AUTOSAR XML (schema 4-0-3)
package /BswM/ServiceSwComponentTypes
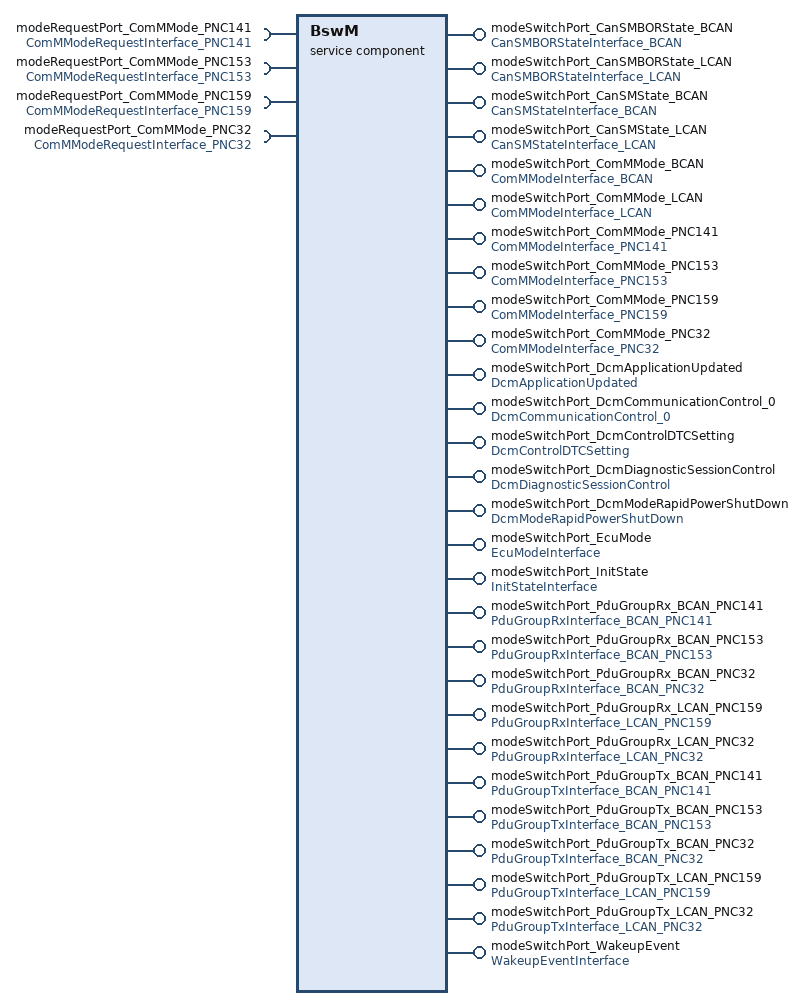
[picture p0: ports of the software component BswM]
  service sw component type BswM
    4 x require port:
      modeRequestPort_ComMMode_PNC141: nonqueued-receiver-com-spec=ComMMode_PNC141, required-interface=ComMModeRequestInterface_PNC141
      modeRequestPort_ComMMode_PNC153: nonqueued-receiver-com-spec=ComMMode_PNC153, required-interface=ComMModeRequestInterface_PNC153
      modeRequestPort_ComMMode_PNC159: nonqueued-receiver-com-spec=ComMMode_PNC159, required-interface=ComMModeRequestInterface_PNC159
      modeRequestPort_ComMMode_PNC32: nonqueued-receiver-com-spec=ComMMode_PNC32, required-interface=ComMModeRequestInterface_PNC32
    28 x provide port:
      modeSwitchPort_CanSMBORState_BCAN: mode-switch-sender-com-spec{enhanced-mode-api=false, mode-group=CanSMBORState_BCAN, queue-length=1}, provided-interface=CanSMBORStateInterface_BCAN
      modeSwitchPort_CanSMBORState_LCAN: mode-switch-sender-com-spec{enhanced-mode-api=false, mode-group=CanSMBORState_LCAN, queue-length=1}, provided-interface=CanSMBORStateInterface_LCAN
      modeSwitchPort_CanSMState_BCAN: mode-switch-sender-com-spec{enhanced-mode-api=false, mode-group=CanSMState_BCAN, queue-length=1}, provided-interface=CanSMStateInterface_BCAN
      modeSwitchPort_CanSMState_LCAN: mode-switch-sender-com-spec{enhanced-mode-api=false, mode-group=CanSMState_LCAN, queue-length=1}, provided-interface=CanSMStateInterface_LCAN
      modeSwitchPort_ComMMode_BCAN: mode-switch-sender-com-spec{enhanced-mode-api=false, mode-group=ComMMode_BCAN, queue-length=1}, provided-interface=ComMModeInterface_BCAN
      modeSwitchPort_ComMMode_LCAN: mode-switch-sender-com-spec{enhanced-mode-api=false, mode-group=ComMMode_LCAN, queue-length=1}, provided-interface=ComMModeInterface_LCAN
      modeSwitchPort_ComMMode_PNC141: mode-switch-sender-com-spec{enhanced-mode-api=false, mode-group=ComMMode_PNC141, queue-length=1}, provided-interface=ComMModeInterface_PNC141
      modeSwitchPort_ComMMode_PNC153: mode-switch-sender-com-spec{enhanced-mode-api=false, mode-group=ComMMode_PNC153, queue-length=1}, provided-interface=ComMModeInterface_PNC153
      modeSwitchPort_ComMMode_PNC159: mode-switch-sender-com-spec{enhanced-mode-api=false, mode-group=ComMMode_PNC159, queue-length=1}, provided-interface=ComMModeInterface_PNC159
      modeSwitchPort_ComMMode_PNC32: mode-switch-sender-com-spec{enhanced-mode-api=false, mode-group=ComMMode_PNC32, queue-length=1}, provided-interface=ComMModeInterface_PNC32
      modeSwitchPort_DcmApplicationUpdated: mode-switch-sender-com-spec{enhanced-mode-api=false, mode-group=DcmApplicationUpdated, queue-length=1}, provided-interface=DcmApplicationUpdated
      modeSwitchPort_DcmCommunicationControl_0: mode-switch-sender-com-spec{enhanced-mode-api=false, mode-group=DcmCommunicationControl_0, queue-length=1}, provided-interface=DcmCommunicationControl_0
      modeSwitchPort_DcmControlDTCSetting: mode-switch-sender-com-spec{enhanced-mode-api=false, mode-group=DcmControlDTCSetting, queue-length=1}, provided-interface=DcmControlDTCSetting
      modeSwitchPort_DcmDiagnosticSessionControl: mode-switch-sender-com-spec{enhanced-mode-api=false, mode-group=DcmDiagnosticSessionControl, queue-length=1}, provided-interface=DcmDiagnosticSessionControl
      modeSwitchPort_DcmModeRapidPowerShutDown: mode-switch-sender-com-spec{enhanced-mode-api=false, mode-group=DcmModeRapidPowerShutDown, queue-length=1}, provided-interface=DcmModeRapidPowerShutDown
      modeSwitchPort_EcuMode: mode-switch-sender-com-spec{enhanced-mode-api=false, mode-group=EcuMode, queue-length=1}, provided-interface=EcuModeInterface
      modeSwitchPort_InitState: mode-switch-sender-com-spec{enhanced-mode-api=false, mode-group=InitState, queue-length=1}, provided-interface=InitStateInterface
      modeSwitchPort_PduGroupRx_BCAN_PNC141: mode-switch-sender-com-spec{enhanced-mode-api=false, mode-group=PduGroupRx_BCAN_PNC141, queue-length=1}, provided-interface=PduGroupRxInterface_BCAN_PNC141
      modeSwitchPort_PduGroupRx_BCAN_PNC153: mode-switch-sender-com-spec{enhanced-mode-api=false, mode-group=PduGroupRx_BCAN_PNC153, queue-length=1}, provided-interface=PduGroupRxInterface_BCAN_PNC153
      modeSwitchPort_PduGroupRx_BCAN_PNC32: mode-switch-sender-com-spec{enhanced-mode-api=false, mode-group=PduGroupRx_BCAN_PNC32, queue-length=1}, provided-interface=PduGroupRxInterface_BCAN_PNC32
      modeSwitchPort_PduGroupRx_LCAN_PNC159: mode-switch-sender-com-spec{enhanced-mode-api=false, mode-group=PduGroupRx_LCAN_PNC159, queue-length=1}, provided-interface=PduGroupRxInterface_LCAN_PNC159
      modeSwitchPort_PduGroupRx_LCAN_PNC32: mode-switch-sender-com-spec{enhanced-mode-api=false, mode-group=PduGroupRx_LCAN_PNC32, queue-length=1}, provided-interface=PduGroupRxInterface_LCAN_PNC32
      modeSwitchPort_PduGroupTx_BCAN_PNC141: mode-switch-sender-com-spec{enhanced-mode-api=false, mode-group=PduGroupTx_BCAN_PNC141, queue-length=1}, provided-interface=PduGroupTxInterface_BCAN_PNC141
      modeSwitchPort_PduGroupTx_BCAN_PNC153: mode-switch-sender-com-spec{enhanced-mode-api=false, mode-group=PduGroupTx_BCAN_PNC153, queue-length=1}, provided-interface=PduGroupTxInterface_BCAN_PNC153
      modeSwitchPort_PduGroupTx_BCAN_PNC32: mode-switch-sender-com-spec{enhanced-mode-api=false, mode-group=PduGroupTx_BCAN_PNC32, queue-length=1}, provided-interface=PduGroupTxInterface_BCAN_PNC32
      modeSwitchPort_PduGroupTx_LCAN_PNC159: mode-switch-sender-com-spec{enhanced-mode-api=false, mode-group=PduGroupTx_LCAN_PNC159, queue-length=1}, provided-interface=PduGroupTxInterface_LCAN_PNC159
      modeSwitchPort_PduGroupTx_LCAN_PNC32: mode-switch-sender-com-spec{enhanced-mode-api=false, mode-group=PduGroupTx_LCAN_PNC32, queue-length=1}, provided-interface=PduGroupTxInterface_LCAN_PNC32
      modeSwitchPort_WakeupEvent: mode-switch-sender-com-spec{enhanced-mode-api=false, mode-group=WakeupEvent, queue-length=1}, provided-interface=WakeupEventInterface
    behavior SwcIB_BswM: data-type-mapping=MAP_ComMMode, handle-termination-and-restart=NO-SUPPORT
      4 x data received event:
        DRE_BswM_Immediate_SwcModeRequest_ComMMode_PNC141_modeRequestPort_ComMMode_PNC141_ComMMode_PNC141: start-on-event=BswM_Immediate_SwcModeRequest_ComMMode_PNC141, data=modeRequestPort_ComMMode_PNC141.ComMMode_PNC141
        DRE_BswM_Immediate_SwcModeRequest_ComMMode_PNC153_modeRequestPort_ComMMode_PNC153_ComMMode_PNC153: start-on-event=BswM_Immediate_SwcModeRequest_ComMMode_PNC153, data=modeRequestPort_ComMMode_PNC153.ComMMode_PNC153
        DRE_BswM_Immediate_SwcModeRequest_ComMMode_PNC159_modeRequestPort_ComMMode_PNC159_ComMMode_PNC159: start-on-event=BswM_Immediate_SwcModeRequest_ComMMode_PNC159, data=modeRequestPort_ComMMode_PNC159.ComMMode_PNC159
        DRE_BswM_Immediate_SwcModeRequest_ComMMode_PNC32_modeRequestPort_ComMMode_PNC32_ComMMode_PNC32: start-on-event=BswM_Immediate_SwcModeRequest_ComMMode_PNC32, data=modeRequestPort_ComMMode_PNC32.ComMMode_PNC32
      32 x runnable:
        BswM_ActionList_RteSwitch_CanSMBORState_BCAN: can-be-invoked-concurrently=true
          mode switch point MSP_BswM_ActionList_RteSwitch_CanSMBORState_BCAN_modeSwitchPort_CanSMBORState_BCAN_CanSMBORState_BCAN: category=TOOL_CONFIGURED, mode-group=modeSwitchPort_CanSMBORState_BCAN.CanSMBORState_BCAN
        BswM_ActionList_RteSwitch_CanSMBORState_LCAN: can-be-invoked-concurrently=true
          mode switch point MSP_BswM_ActionList_RteSwitch_CanSMBORState_LCAN_modeSwitchPort_CanSMBORState_LCAN_CanSMBORState_LCAN: category=TOOL_CONFIGURED, mode-group=modeSwitchPort_CanSMBORState_LCAN.CanSMBORState_LCAN
        BswM_ActionList_RteSwitch_CanSMState_BCAN: can-be-invoked-concurrently=true
          mode switch point MSP_BswM_ActionList_RteSwitch_CanSMState_BCAN_modeSwitchPort_CanSMState_BCAN_CanSMState_BCAN: category=TOOL_CONFIGURED, mode-group=modeSwitchPort_CanSMState_BCAN.CanSMState_BCAN
        BswM_ActionList_RteSwitch_CanSMState_LCAN: can-be-invoked-concurrently=true
          mode switch point MSP_BswM_ActionList_RteSwitch_CanSMState_LCAN_modeSwitchPort_CanSMState_LCAN_CanSMState_LCAN: category=TOOL_CONFIGURED, mode-group=modeSwitchPort_CanSMState_LCAN.CanSMState_LCAN
        BswM_ActionList_RteSwitch_ComMMode_BCAN: can-be-invoked-concurrently=true
          mode switch point MSP_BswM_ActionList_RteSwitch_ComMMode_BCAN_modeSwitchPort_ComMMode_BCAN_ComMMode_BCAN: category=TOOL_CONFIGURED, mode-group=modeSwitchPort_ComMMode_BCAN.ComMMode_BCAN
        BswM_ActionList_RteSwitch_ComMMode_LCAN: can-be-invoked-concurrently=true
          mode switch point MSP_BswM_ActionList_RteSwitch_ComMMode_LCAN_modeSwitchPort_ComMMode_LCAN_ComMMode_LCAN: category=TOOL_CONFIGURED, mode-group=modeSwitchPort_ComMMode_LCAN.ComMMode_LCAN
        BswM_ActionList_RteSwitch_ComMMode_PNC141: can-be-invoked-concurrently=true
          mode switch point MSP_BswM_ActionList_RteSwitch_ComMMode_PNC141_modeSwitchPort_ComMMode_PNC141_ComMMode_PNC141: category=TOOL_CONFIGURED, mode-group=modeSwitchPort_ComMMode_PNC141.ComMMode_PNC141
        BswM_ActionList_RteSwitch_ComMMode_PNC153: can-be-invoked-concurrently=true
          mode switch point MSP_BswM_ActionList_RteSwitch_ComMMode_PNC153_modeSwitchPort_ComMMode_PNC153_ComMMode_PNC153: category=TOOL_CONFIGURED, mode-group=modeSwitchPort_ComMMode_PNC153.ComMMode_PNC153
        BswM_ActionList_RteSwitch_ComMMode_PNC159: can-be-invoked-concurrently=true
          mode switch point MSP_BswM_ActionList_RteSwitch_ComMMode_PNC159_modeSwitchPort_ComMMode_PNC159_ComMMode_PNC159: category=TOOL_CONFIGURED, mode-group=modeSwitchPort_ComMMode_PNC159.ComMMode_PNC159
        BswM_ActionList_RteSwitch_ComMMode_PNC32: can-be-invoked-concurrently=true
          mode switch point MSP_BswM_ActionList_RteSwitch_ComMMode_PNC32_modeSwitchPort_ComMMode_PNC32_ComMMode_PNC32: category=TOOL_CONFIGURED, mode-group=modeSwitchPort_ComMMode_PNC32.ComMMode_PNC32
        BswM_ActionList_RteSwitch_DcmApplicationUpdated: can-be-invoked-concurrently=true
          mode switch point MSP_BswM_ActionList_RteSwitch_DcmApplicationUpdated_modeSwitchPort_DcmApplicationUpdated_DcmApplicationUpdated: category=TOOL_CONFIGURED, mode-group=modeSwitchPort_DcmApplicationUpdated.DcmApplicationUpdated
        BswM_ActionList_RteSwitch_DcmCommunicationControl_0: can-be-invoked-concurrently=true
          mode switch point MSP_BswM_ActionList_RteSwitch_DcmCommunicationControl_0_modeSwitchPort_DcmCommunicationControl_0_DcmCommunicationControl_0: category=TOOL_CONFIGURED, mode-group=modeSwitchPort_DcmCommunicationControl_0.DcmCommunicationControl_0
        BswM_ActionList_RteSwitch_DcmControlDTCSetting: can-be-invoked-concurrently=true
          mode switch point MSP_BswM_ActionList_RteSwitch_DcmControlDTCSetting_modeSwitchPort_DcmControlDTCSetting_DcmControlDTCSetting: category=TOOL_CONFIGURED, mode-group=modeSwitchPort_DcmControlDTCSetting.DcmControlDTCSetting
        BswM_ActionList_RteSwitch_DcmDiagnosticSessionControl: can-be-invoked-concurrently=true
          mode switch point MSP_BswM_ActionList_RteSwitch_DcmDiagnosticSessionControl_modeSwitchPort_DcmDiagnosticSessionControl_DcmDiagnosticSessionControl: category=TOOL_CONFIGURED, mode-group=modeSwitchPort_DcmDiagnosticSessionControl.DcmDiagnosticSessionControl
        BswM_ActionList_RteSwitch_DcmModeRapidPowerShutDown: can-be-invoked-concurrently=true
          mode switch point MSP_BswM_ActionList_RteSwitch_DcmModeRapidPowerShutDown_modeSwitchPort_DcmModeRapidPowerShutDown_DcmModeRapidPowerShutDown: category=TOOL_CONFIGURED, mode-group=modeSwitchPort_DcmModeRapidPowerShutDown.DcmModeRapidPowerShutDown
        BswM_ActionList_RteSwitch_EcuMode: can-be-invoked-concurrently=true
          mode switch point MSP_BswM_ActionList_RteSwitch_EcuMode_modeSwitchPort_EcuMode_EcuMode: category=TOOL_CONFIGURED, mode-group=modeSwitchPort_EcuMode.EcuMode
        BswM_ActionList_RteSwitch_InitState: can-be-invoked-concurrently=true
          mode switch point MSP_BswM_ActionList_RteSwitch_InitState_modeSwitchPort_InitState_InitState: category=TOOL_CONFIGURED, mode-group=modeSwitchPort_InitState.InitState
        BswM_ActionList_RteSwitch_PduGroupRx_BCAN_PNC141: can-be-invoked-concurrently=true
          mode switch point MSP_BswM_ActionList_RteSwitch_PduGroupRx_BCAN_PNC141_modeSwitchPort_PduGroupRx_BCAN_PNC141_PduGroupRx_BCAN_PNC141: category=TOOL_CONFIGURED, mode-group=modeSwitchPort_PduGroupRx_BCAN_PNC141.PduGroupRx_BCAN_PNC141
        BswM_ActionList_RteSwitch_PduGroupRx_BCAN_PNC153: can-be-invoked-concurrently=true
          mode switch point MSP_BswM_ActionList_RteSwitch_PduGroupRx_BCAN_PNC153_modeSwitchPort_PduGroupRx_BCAN_PNC153_PduGroupRx_BCAN_PNC153: category=TOOL_CONFIGURED, mode-group=modeSwitchPort_PduGroupRx_BCAN_PNC153.PduGroupRx_BCAN_PNC153
        BswM_ActionList_RteSwitch_PduGroupRx_BCAN_PNC32: can-be-invoked-concurrently=true
          mode switch point MSP_BswM_ActionList_RteSwitch_PduGroupRx_BCAN_PNC32_modeSwitchPort_PduGroupRx_BCAN_PNC32_PduGroupRx_BCAN_PNC32: category=TOOL_CONFIGURED, mode-group=modeSwitchPort_PduGroupRx_BCAN_PNC32.PduGroupRx_BCAN_PNC32
        BswM_ActionList_RteSwitch_PduGroupRx_LCAN_PNC159: can-be-invoked-concurrently=true
          mode switch point MSP_BswM_ActionList_RteSwitch_PduGroupRx_LCAN_PNC159_modeSwitchPort_PduGroupRx_LCAN_PNC159_PduGroupRx_LCAN_PNC159: category=TOOL_CONFIGURED, mode-group=modeSwitchPort_PduGroupRx_LCAN_PNC159.PduGroupRx_LCAN_PNC159
        BswM_ActionList_RteSwitch_PduGroupRx_LCAN_PNC32: can-be-invoked-concurrently=true
          mode switch point MSP_BswM_ActionList_RteSwitch_PduGroupRx_LCAN_PNC32_modeSwitchPort_PduGroupRx_LCAN_PNC32_PduGroupRx_LCAN_PNC32: category=TOOL_CONFIGURED, mode-group=modeSwitchPort_PduGroupRx_LCAN_PNC32.PduGroupRx_LCAN_PNC32
        BswM_ActionList_RteSwitch_PduGroupTx_BCAN_PNC141: can-be-invoked-concurrently=true
          mode switch point MSP_BswM_ActionList_RteSwitch_PduGroupTx_BCAN_PNC141_modeSwitchPort_PduGroupTx_BCAN_PNC141_PduGroupTx_BCAN_PNC141: category=TOOL_CONFIGURED, mode-group=modeSwitchPort_PduGroupTx_BCAN_PNC141.PduGroupTx_BCAN_PNC141
        BswM_ActionList_RteSwitch_PduGroupTx_BCAN_PNC153: can-be-invoked-concurrently=true
          mode switch point MSP_BswM_ActionList_RteSwitch_PduGroupTx_BCAN_PNC153_modeSwitchPort_PduGroupTx_BCAN_PNC153_PduGroupTx_BCAN_PNC153: category=TOOL_CONFIGURED, mode-group=modeSwitchPort_PduGroupTx_BCAN_PNC153.PduGroupTx_BCAN_PNC153
        BswM_ActionList_RteSwitch_PduGroupTx_BCAN_PNC32: can-be-invoked-concurrently=true
          mode switch point MSP_BswM_ActionList_RteSwitch_PduGroupTx_BCAN_PNC32_modeSwitchPort_PduGroupTx_BCAN_PNC32_PduGroupTx_BCAN_PNC32: category=TOOL_CONFIGURED, mode-group=modeSwitchPort_PduGroupTx_BCAN_PNC32.PduGroupTx_BCAN_PNC32
        BswM_ActionList_RteSwitch_PduGroupTx_LCAN_PNC159: can-be-invoked-concurrently=true
          mode switch point MSP_BswM_ActionList_RteSwitch_PduGroupTx_LCAN_PNC159_modeSwitchPort_PduGroupTx_LCAN_PNC159_PduGroupTx_LCAN_PNC159: category=TOOL_CONFIGURED, mode-group=modeSwitchPort_PduGroupTx_LCAN_PNC159.PduGroupTx_LCAN_PNC159
        BswM_ActionList_RteSwitch_PduGroupTx_LCAN_PNC32: can-be-invoked-concurrently=true
          mode switch point MSP_BswM_ActionList_RteSwitch_PduGroupTx_LCAN_PNC32_modeSwitchPort_PduGroupTx_LCAN_PNC32_PduGroupTx_LCAN_PNC32: category=TOOL_CONFIGURED, mode-group=modeSwitchPort_PduGroupTx_LCAN_PNC32.PduGroupTx_LCAN_PNC32
        BswM_ActionList_RteSwitch_WakeupEvent: can-be-invoked-concurrently=true
          mode switch point MSP_BswM_ActionList_RteSwitch_WakeupEvent_modeSwitchPort_WakeupEvent_WakeupEvent: category=TOOL_CONFIGURED, mode-group=modeSwitchPort_WakeupEvent.WakeupEvent
        BswM_Immediate_SwcModeRequest_ComMMode_PNC141
          data-receive-point-by-arguments:
            access DRPBA_BswM_Immediate_SwcModeRequest_ComMMode_PNC141_modeRequestPort_ComMMode_PNC141_ComMMode_PNC141: category=TOOL_CONFIGURED, accessed-variable=modeRequestPort_ComMMode_PNC141.ComMMode_PNC141
        BswM_Immediate_SwcModeRequest_ComMMode_PNC153
          data-receive-point-by-arguments:
            access DRPBA_BswM_Immediate_SwcModeRequest_ComMMode_PNC153_modeRequestPort_ComMMode_PNC153_ComMMode_PNC153: category=TOOL_CONFIGURED, accessed-variable=modeRequestPort_ComMMode_PNC153.ComMMode_PNC153
        BswM_Immediate_SwcModeRequest_ComMMode_PNC159
          data-receive-point-by-arguments:
            access DRPBA_BswM_Immediate_SwcModeRequest_ComMMode_PNC159_modeRequestPort_ComMMode_PNC159_ComMMode_PNC159: category=TOOL_CONFIGURED, accessed-variable=modeRequestPort_ComMMode_PNC159.ComMMode_PNC159
        BswM_Immediate_SwcModeRequest_ComMMode_PNC32
          data-receive-point-by-arguments:
            access DRPBA_BswM_Immediate_SwcModeRequest_ComMMode_PNC32_modeRequestPort_ComMMode_PNC32_ComMMode_PNC32: category=TOOL_CONFIGURED, accessed-variable=modeRequestPort_ComMMode_PNC32.ComMMode_PNC32
  swc implementation SwcImplementation_BswM: programming-language=C, swc-bsw-mapping=SwcBswMapping_BswM, behavior=SwcIB_BswM
package /BswM/SwcBswMappings
  swc bsw mapping SwcBswMapping_BswM: bsw-behavior=BswIB_BswM, swc-behavior=SwcIB_BswM
